# MIMXRT1061 register map
Vendor: nxp.com; File version: 1.0
CPU: CM7 r0p1, little endian, MPU, FPU, VTOR, 4 interrupt priority bits
Registers are 32-bit, read-write, reset 0x0 unless marked. A register's access mark holds for its fields unless they carry their own. Offsets are from the block's base; [hi:lo] are bit positions; 'fields as' and 'values as' point back to an identical list.

## SPDIF
Base 0x40380000
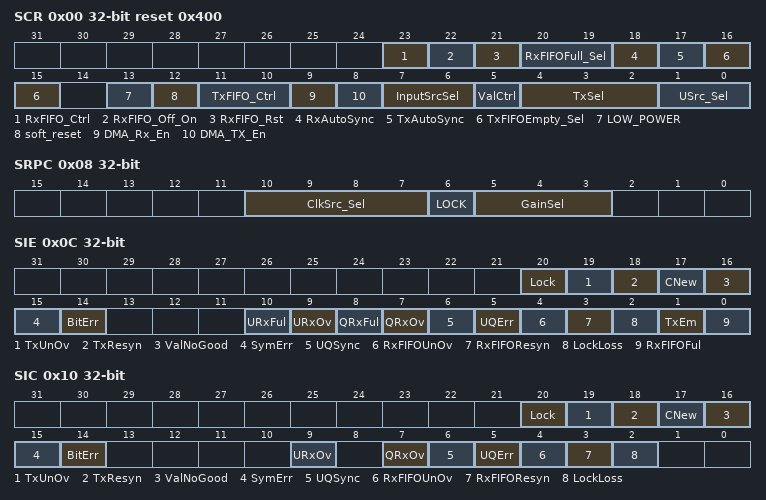
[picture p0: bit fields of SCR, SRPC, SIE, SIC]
0x00 SCR reset 0x400 — SPDIF Configuration Register
  [23] RxFIFO_Ctrl
    0=Normal operation; 1=always_zero (Always read zero from Rx data register)
  [22] RxFIFO_Off_On
    0=on_0 (SPDIF Rx FIFO is on); 1=off_1 (SPDIF Rx FIFO is off. Does not accept data from interface)
  [21] RxFIFO_Rst
    0=Normal operation; 1=reset_one (Reset register to 1 sample remaining)
  [20:19] RxFIFOFull_Sel
    0=full_int_1 (Full interrupt if at least 1 sample in Rx left and right FIFOs); 1=full_int_4 (Full interrupt if at least 4 sample in Rx left and right FIFOs); 2=full_int_8 (Full interrupt if at least 8 sample in Rx left and right FIFOs); 3=full_int_16 (Full interrupt if at least 16 sample in Rx left and right FIFO)
  [18] RxAutoSync
    0=off (Rx FIFO auto sync off); 1=on (RxFIFO auto sync on)
  [17] TxAutoSync
    0=off (Tx FIFO auto sync off); 1=on (Tx FIFO auto sync on)
  [16:15] TxFIFOEmpty_Sel
    0=empty_int_0 (Empty interrupt if 0 sample in Tx left and right FIFOs); 1=empty_int_4 (Empty interrupt if at most 4 sample in Tx left and right FIFOs); 2=empty_int_8 (Empty interrupt if at most 8 sample in Tx left and right FIFOs); 3=empty_int_12 (Empty interrupt if at most 12 sample in Tx left and right FIFOs)
  [13] LOW_POWER
  [12] soft_reset
  [11:10] TxFIFO_Ctrl
    0=send_zero (Send out digital zero on SPDIF Tx); 1=normal (Tx Normal operation); 2=reset_one (Reset to 1 sample remaining)
  [9] DMA_Rx_En
  [8] DMA_TX_En
  [7:6] InputSrcSel
    0=spdif_in; 1=none_sel_1; 2=none_sel_2; 3=none_sel_3
  [5] ValCtrl
    0=always_set (Outgoing Validity always set); 1=always_clear (Outgoing Validity always clear)
  [4:2] TxSel
    0=off_out0 (Off and output 0); 1=feedthru (Feed-through SPDIFIN); 5=normal_op (Tx Normal operation)
  [1:0] USrc_Sel
    0=none (No embedded U channel); 1=spdif_rxblock (U channel from SPDIF receive block (CD mode)); 3=chip_transmit (U channel from on chip transmitter)
0x04 SRCD — CDText Control Register
  [1] USyncMode
    0=non_cddata; 1=cduser_chsubcode (CD user channel subcode)
0x08 SRPC — PhaseConfig Register
  [10:7] ClkSrc_Sel
    0=clksrc_0b0000 (if (DPLL Locked) SPDIF_RxClk else REF_CLK_32K (XTALOSC)); 1=clksrc_0b0001 (if (DPLL Locked) SPDIF_RxClk else tx_clk (SPDIF0_CLK_ROOT)); 3=clksrc_0b0011 (if (DPLL Locked) SPDIF_RxClk else SPDIF_EXT_CLK); 5=clksrc_0b0101 (REF_CLK_32K (XTALOSC)); 6=clksrc_0b0110 (tx_clk (SPDIF0_CLK_ROOT)); 8=clksrc_0b1000 (SPDIF_EXT_CLK)
  [6] LOCK ro
  [5:3] GainSel
    0=24*(2**10); 1=16*(2**10); 2=12*(2**10); 3=8*(2**10); 4=6*(2**10); 5=4*(2**10); 6=3*(2**10)
0x0C SIE — InterruptEn Register
  [20] Lock, [19] TxUnOv, [18] TxResyn, [17] CNew, [16] ValNoGood, [15] SymErr, [14] BitErr, [10] URxFul, [9] URxOv, [8] QRxFul, [7] QRxOv, [6] UQSync, [5] UQErr, [4] RxFIFOUnOv, [3] RxFIFOResyn, [2] LockLoss, [1] TxEm, [0] RxFIFOFul
0x10 SIC wo (SIC_SIS view) — InterruptClear Register
  [20] Lock, [19] TxUnOv, [18] TxResyn, [17] CNew, [16] ValNoGood, [15] SymErr, [14] BitErr, [9] URxOv, [7] QRxOv, [6] UQSync, [5] UQErr, [4] RxFIFOUnOv, [3] RxFIFOResyn, [2] LockLoss
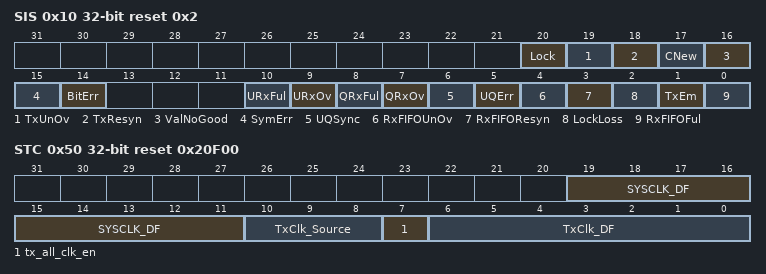
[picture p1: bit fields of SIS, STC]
0x10 SIS ro reset 0x2 (SIC_SIS view) — InterruptStat Register
  fields as SIE
0x14 SRL ro — SPDIFRxLeft Register
  [23:0] RxDataLeft
0x18 SRR ro — SPDIFRxRight Register
  [23:0] RxDataRight
0x1C SRCSH ro — SPDIFRxCChannel_h Register
  [23:0] RxCChannel_h
0x20 SRCSL ro — SPDIFRxCChannel_l Register
  [23:0] RxCChannel_l
0x24 SRU ro — UchannelRx Register
  [23:0] RxUChannel
0x28 SRQ ro — QchannelRx Register
  [23:0] RxQChannel
0x2C STL wo — SPDIFTxLeft Register
  [23:0] TxDataLeft
0x30 STR wo — SPDIFTxRight Register
  [23:0] TxDataRight
0x34 STCSCH — SPDIFTxCChannelCons_h Register
  [23:0] TxCChannelCons_h
0x38 STCSCL — SPDIFTxCChannelCons_l Register
  [23:0] TxCChannelCons_l
0x44 SRFM ro — FreqMeas Register
  [23:0] FreqMeas
0x50 STC reset 0x20F00 — SPDIFTxClk Register
  [19:11] SYSCLK_DF
    0=no_clk (no clock signal); 1=div2 (divider factor is 2); 0x1FF=div512 (divider factor is 512)
  [10:8] TxClk_Source
    0=txclk_src_0b000 (REF_CLK_32K input (XTALOSC 32 kHz clock)); 1=txclk_src_0b001 (tx_clk input (from SPDIF0_CLK_ROOT. See clock control block for more information.)); 3=txclk_src_0b011 (SPDIF_EXT_CLK, from pads); 5=txclk_src_0b101 (ipg_clk input (frequency divided))
  [7] tx_all_clk_en
    0=disable transfer clock; 1=enable transfer clock
  [6:0] TxClk_DF
    0=div1 (divider factor is 1); 1=div2 (divider factor is 2); 127=div128 (divider factor is 128)
